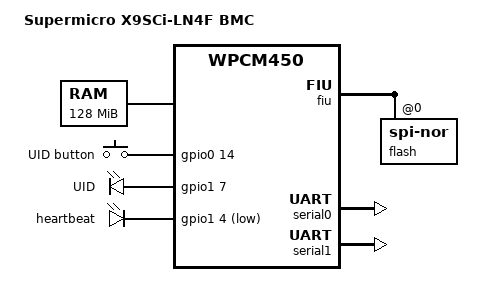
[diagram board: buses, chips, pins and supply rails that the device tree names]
/dts-v1/;
/memreserve/ 0x07000000 0x01000000;
#include "nuvoton-wpcm450.dtsi"
#include <dt-bindings/input/linux-event-codes.h>
#include <dt-bindings/gpio/gpio.h>
/ {
	model = "Supermicro X9SCi-LN4F BMC";
	compatible = "supermicro,x9sci-ln4f-bmc", "nuvoton,wpcm450";
	aliases {
		serial0 = &serial0;
		serial1 = &serial1;
	};
	chosen {
		stdout-path = "serial0:115200n8";
	};
	memory@0 {
		device_type = "memory";
		reg = <0 0x08000000>;  
	};
	gpio-keys {
		compatible = "gpio-keys";
		pinctrl-names = "default";
		pinctrl-0 = <&key_pins>;
		uid {
			label = "UID button";
			linux,code = <KEY_HOME>;
			gpios = <&gpio0 14 GPIO_ACTIVE_HIGH>;
		};
	};
	gpio-leds {
		compatible = "gpio-leds";
		pinctrl-names = "default";
		pinctrl-0 = <&led_pins>;
		uid {
			label = "UID";
			gpios = <&gpio1 7 GPIO_ACTIVE_HIGH>;
		};
		heartbeat {
			label = "heartbeat";
			gpios = <&gpio1 4 GPIO_ACTIVE_LOW>;
		};
	};
};
&fiu {
	status = "okay";
	flash@0 {
		reg = <0>;
		compatible = "jedec,spi-nor";
	};
};
&gpio0 {
	gpio-line-names =
		  "", "host-reset-control-n", "", "", "", "", "", "",
		  "", "", "", "", "power-chassis-control-n", "", "uid-button", "";
};
&gpio1 {
	gpio-line-names =
		  "", "", "", "", "led-heartbeat", "", "", "led-uid",
		  "", "", "", "", "", "", "", "";
};
&gpio4 {
	gpio-line-names =
		  "", "", "", "", "", "", "", "",
		  "", "", "", "", "", "", "", "power-chassis-good";
};
&pinctrl {
	key_pins: mux-keys {
		groups = "gspi", "sspi";
		function = "gpio";
	};
	led_pins: mux-leds {
		groups = "hg3", "hg0", "pwm4";
		function = "gpio";
	};
};
&serial0 {
	status = "okay";
};
&serial1 {
	status = "okay";
};
